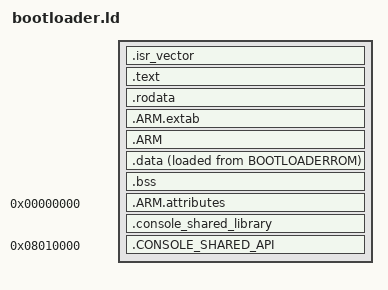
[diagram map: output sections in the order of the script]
INCLUDE ../memory_map.ld

ENTRY(Reset_Handler)

/* Highest address of the user mode stack */
_estack = ORIGIN(RAM) + LENGTH(RAM);    /* end of RAM */

/* Define output sections */
SECTIONS
{
  /* The startup code goes first into FLASH */
  .isr_vector :
  {
    . = ALIGN(4);
    KEEP(*(.isr_vector)) /* Startup code */
    . = ALIGN(4);
  } >BOOTLOADERROM

  /* The program code and other data goes into FLASH */
  .text :
  {
    . = ALIGN(4);
    *(.text)           /* .text sections (code) */
    *(.text*)          /* .text* sections (code) */
    *(.glue_7)         /* glue arm to thumb code */
    *(.glue_7t)        /* glue thumb to arm code */
    *(.eh_frame)

    KEEP (*(.init))
    KEEP (*(.fini))

    . = ALIGN(4);
    _etext = .;        /* define a global symbols at end of code */
  } >BOOTLOADERROM

  /* Constant data goes into FLASH */
  .rodata :
  {
    . = ALIGN(4);
    *(.rodata)         /* .rodata sections (constants, strings, etc.) */
    *(.rodata*)        /* .rodata* sections (constants, strings, etc.) */
    . = ALIGN(4);
  } >BOOTLOADERROM

  .ARM.extab   : { *(.ARM.extab* .gnu.linkonce.armextab.*) } >BOOTLOADERROM
  .ARM : {
    __exidx_start = .;
    *(.ARM.exidx*)
    __exidx_end = .;
  } >BOOTLOADERROM

  /* used by the startup to initialize data */
  _sidata = LOADADDR(.data);

  /* Initialized data sections goes into RAM, load LMA copy after code */
  .data : 
  {
    . = ALIGN(4);
    _sdata = .;        /* create a global symbol at data start */
    *(.data)           /* .data sections */
    *(.data*)          /* .data* sections */

    . = ALIGN(4);
    _edata = .;        /* define a global symbol at data end */
  } >RAM AT> BOOTLOADERROM
  
  /* Uninitialized data section */
  . = ALIGN(4);
  .bss :
  {
    /* This is used by the startup in order to initialize the .bss secion */
    _sbss = .;         /* define a global symbol at bss start */
    __bss_start__ = _sbss;
    *(.bss)
    *(.bss*)
    *(COMMON)

    . = ALIGN(4);
    _ebss = .;         /* define a global symbol at bss end */
    __bss_end__ = _ebss;
  } >RAM

  .ARM.attributes 0 : { *(.ARM.attributes) }

  .console_shared_library :
  {
    . = ALIGN(4);
    __console_shared_library_start__ = .;
    *(.console_shared_library*)
    __console_shared_library_end__ = .;
  } >LIBRARYROM

  .CONSOLE_SHARED_API 0x8010000:
  {
    KEEP(*(.CONSOLE_SHARED_API))
  } >LIBRARYROM
  
  ASSERT(LENGTH(LIBRARYROM) >= (__console_shared_library_end__ - __console_shared_library_start__), "LIBRARYROM OVERFLOW" )
}


